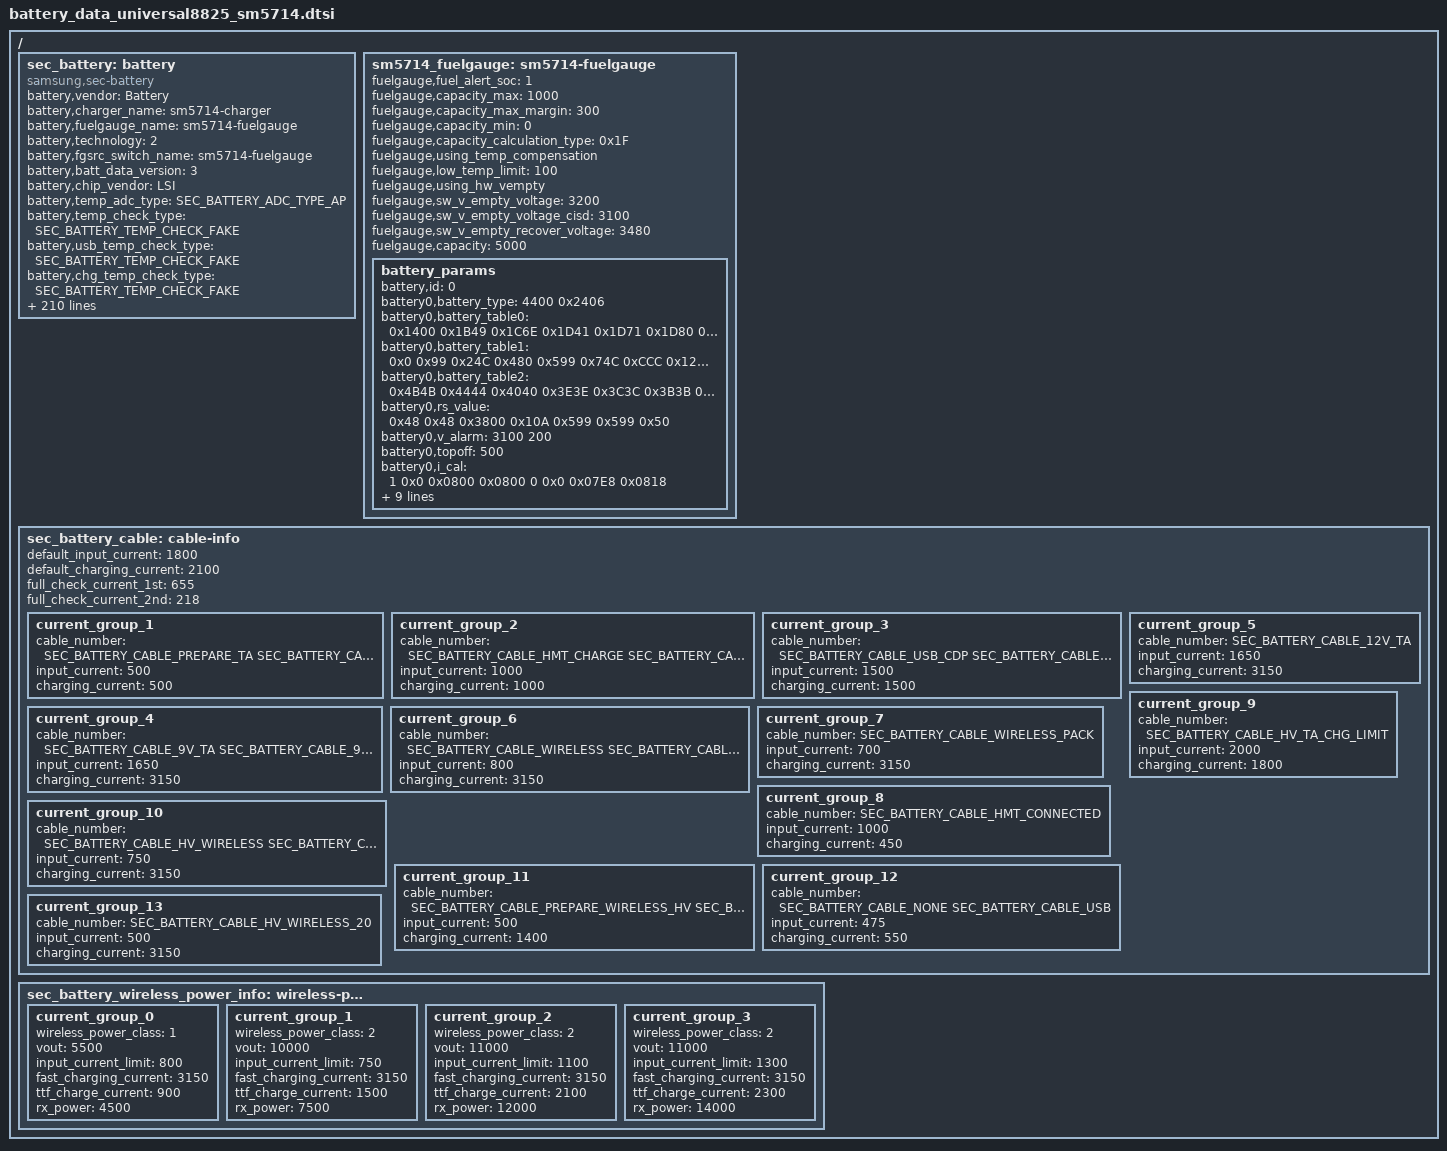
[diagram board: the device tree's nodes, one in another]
/*
 * SAMSUNG UNIVERSAL8825 board device tree source
 *
 * Copyright (c) 2020 Samsung Electronics Co., Ltd.
 *		http://www.samsung.com
 *
 * This program is free software; you can redistribute it and/or modify
 * it under the terms of the GNU General Public License version 2 as
 * published by the Free Software Foundation.
 */

#include <dt-bindings/battery/sec-battery.h>

/ {
	fragment@battery {
		target-path = "/";
		__overlay__ {
			sec_battery: battery {
				status = "okay";
				compatible = "samsung,sec-battery";

				pinctrl-names = "default";

				battery,vendor = "Battery";
				battery,charger_name = "sm5714-charger";
				battery,fuelgauge_name = "sm5714-fuelgauge";
				battery,technology = <2>; /* POWER_SUPPLY_TECHNOLOGY_LION */
				battery,fgsrc_switch_name = "sm5714-fuelgauge"; /* Fuelgauge voltage source */

				battery,batt_data_version = <3>;

				battery,chip_vendor = "LSI";
				battery,temp_adc_type = <SEC_BATTERY_ADC_TYPE_AP>;

				battery,temp_check_type = <SEC_BATTERY_TEMP_CHECK_FAKE>;
				battery,usb_temp_check_type = <SEC_BATTERY_TEMP_CHECK_FAKE>;
				battery,chg_temp_check_type = <SEC_BATTERY_TEMP_CHECK_FAKE>;
				battery,wpc_temp_check_type = <SEC_BATTERY_TEMP_CHECK_FAKE>;
				battery,dchg_temp_check_type = <SEC_BATTERY_TEMP_CHECK_FAKE>;

				battery,thermal_source = <SEC_BATTERY_THERMAL_SOURCE_ADC>;
				battery,usb_thermal_source = <SEC_BATTERY_THERMAL_SOURCE_ADC>;
				battery,chg_thermal_source = <SEC_BATTERY_THERMAL_SOURCE_ADC>;
				battery,wpc_thermal_source = <SEC_BATTERY_THERMAL_SOURCE_ADC>;
				battery,dchg_thermal_source = <SEC_BATTERY_THERMAL_SOURCE_CHG_ADC>;

				battery,polling_time = <10 30 30 30 3600>;

				battery,temp_table_adc = <311 360 416 483 562 655 763 889 1033 1162 1340 1539
					1754 1978 2219 2459 2698 2922 3123 3304 3465 3588 3679>;
				battery,temp_table_data = <900 850 800 750 700 650 600 550 500 450 400 350
					300 250 200 150 100 50 0 (-50) (-100) (-150) (-200)>;

				battery,usb_temp_table_adc = <268 326 384 453 532 624 733 859 1001 1161 1356 1558
					1774 2000 2235 2470 2692 2913 3100 3278 3431 3539 3665>;
				battery,usb_temp_table_data = <900 850 800 750 700 650 600 550 500 450 400 350
					300 250 200 150 100 50 0 (-50) (-100) (-150) (-200)>;

				battery,chg_temp_table_adc = <221 276 331 398 474 564 667 794 935 1096 1285 1489
					1711 1945 2185 2428 2665 2895 3103 3291 3446 3568 3701>;
				battery,chg_temp_table_data = <900 850 800 750 700 650 600 550 500 450 400 350
					300 250 200 150 100 50 0 (-50) (-100) (-150) (-200)>;

				battery,wpc_temp_table_adc = <311 360 416 483 562 655 763 889 1033 1162 1340 1539
					1754 1978 2219 2459 2698 2922 3123 3304 3465 3588 3679>;
				battery,wpc_temp_table_data = <900 850 800 750 700 650 600 550 500 450 400 350
					300 250 200 150 100 50 0 (-50) (-100) (-150) (-200)>;

				battery,dchg_temp_table_adc = <89148 112608 136068 164220 197064 236946 283866 337824 401166 471546 548964 640458
					736644 842214 947784 1058046 1163616 1264494 1358334 1440444 1510824 1569474 1618740>;
				battery,dchg_temp_table_data = <900 850 800 750 700 650 600 550 500 450 400 350
					300 250 200 150 100 50 0 (-50) (-100) (-150) (-200)>;

				battery,wireless_cc_cv = <85>;
				battery,wpc_cc_cv_vout = <5500>;
				battery,wpc_cv_call_vout = <5000>;
				battery,wpc_cc_call_vout = <5000>;
				battery,hv_vout_wa = <0x41>; /* WC vout 10.0V */
				battery,adc_check_count = <5>;

				battery,cable_check_type = <SEC_BATTERY_CABLE_CHECK_PSY>;
				battery,cable_source_type = <SEC_BATTERY_CABLE_SOURCE_EXTERNAL>; 
				battery,polling_type = <SEC_BATTERY_MONITOR_ALARM>;
				battery,monitor_initial_count = <0>;

				battery,battery_check_type = <0>; /* SEC_BATTERY_CHECK_NONE */
				battery,check_count = <0>;
				battery,check_adc_max = <1440>;
				battery,check_adc_min = <0>;

				battery,ovp_uvlo_check_type = <SEC_BATTERY_OVP_UVLO_CHGPOLLING>; 

				battery,temp_check_count = <1>;

				battery,overheatlimit_threshold = <700>;
				battery,overheatlimit_recovery = <680>;
				battery,wire_warm_overheat_thresh = <500>;
				battery,wire_normal_warm_thresh = <410>;
				battery,wire_cool1_normal_thresh = <180>;
				battery,wire_cool2_cool1_thresh = <150>;
				battery,wire_cool3_cool2_thresh = <50>;
				battery,wire_cold_cool3_thresh = <0>;
				battery,wireless_warm_overheat_thresh = <450>;
				battery,wireless_normal_warm_thresh = <410>;
				battery,wireless_cool1_normal_thresh = <180>;
				battery,wireless_cool2_cool1_thresh = <150>;
				battery,wireless_cool3_cool2_thresh = <50>;
				battery,wireless_cold_cool3_thresh = <0>;

				battery,wire_warm_current = <1573>;	/* 0.36C */
				battery,wire_cool1_current = <3146>;	/* 0.72C */
				battery,wire_cool2_current = <1048>;	/* 0.24C */
				battery,wire_cool3_current = <437>;	/* 0.1C */
				battery,wireless_warm_current = <1048>;		/* 0.24C */
				battery,wireless_cool1_current = <3146>;	/* 0.72C */
				battery,wireless_cool2_current = <1048>;	/* 0.24C */
				battery,wireless_cool3_current = <437>;		/* 0.1C */

				battery,tx_high_threshold = <450>;
				battery,tx_high_recovery = <400>;
				battery,tx_low_threshold = <0>;
				battery,tx_low_recovery = <50>;
				battery,full_check_type = <2>; /* SEC_BATTERY_FULLCHARGED_FUELGAUGE */
				battery,full_check_type_2nd = <2>; /* SEC_BATTERY_FULLCHARGED_FUELGAUGE */
				battery,full_check_count = <1>;
				battery,chg_gpio_full_check = <0>;
				battery,chg_polarity_full_check = <1>;

				battery,chg_high_temp = <470>;
				battery,chg_high_temp_recovery = <450>;

				battery,dchg_high_temp = <520>;
				battery,dchg_high_temp_recovery = <460>;
				battery,dchg_high_batt_temp = <400>;
				battery,dchg_high_batt_temp_recovery = <380>;

				battery,chg_input_limit_current = <1000>;
				battery,chg_charging_limit_current = <1900>;
				battery,dchg_input_limit_current = <1000>;
				battery,dchg_charging_limit_current = <2000>;

				battery,charging_limit_by_tx_check = <1>;
				battery,charging_limit_current_by_tx = <1200>;

				battery,wpc_temp_control_source = <1>; /* TEMP_CONTROL_SOURCE_BAT_THM = WPC_THM */
				battery,wpc_high_temp = <400>;
				battery,wpc_high_temp_recovery = <380>;
				battery,wpc_input_limit_current = <600>;
				battery,wpc_charging_limit_current = <1000>;
				battery,wpc_temp_lcd_on_control_source = <1>; /* TEMP_CONTROL_SOURCE_BAT_THM = WPC_THM */
				battery,wpc_lcd_on_high_temp = <400>;
				battery,wpc_lcd_on_high_temp_rec = <380>;
				battery,wpc_lcd_on_input_limit_current = <450>;

				battery,wpc_store_high_temp = <360>;
				battery,wpc_store_high_temp_recovery = <340>;
				battery,wpc_store_lcd_on_high_temp = <360>;
				battery,wpc_store_lcd_on_high_temp_rec = <300>;
				battery,wpc_store_lcd_on_charging_limit_current = <400>;

				battery,sleep_mode_limit_current = <800>;
				battery,wc_full_input_limit_current = <100>;

				battery,mix_high_temp = <420>;
				battery,mix_high_chg_temp = <500>;
				battery,mix_high_dc_temp = <580>;
				battery,mix_high_temp_recovery = <390>;

				/* SEC_BATTERY_FULL_CONDITION_NOTIMEFULL | SEC_BATTERY_FULL_CONDITION_VCELL */
				battery,full_condition_type = <9>;
				battery,full_condition_soc = <93>;
				battery,full_condition_vcell = <4330>;

				battery,recharge_check_count = <1>;
				battery,recharge_condition_type = <4>; /* SEC_BATTERY_RECHARGE_CONDITION_VCELL */
				battery,recharge_condition_soc = <98>;
				battery,recharge_condition_vcell = <4310>;

				battery,charging_total_time = <14400>;
				battery,hv_charging_total_time = <10800>;
				battery,normal_charging_total_time = <18000>;
				battery,usb_charging_total_time = <36000>;
				battery,recharging_total_time = <5400>;
				battery,charging_reset_time = <0>;

				battery,chg_float_voltage = <4380>;
				battery,chg_ocp_current = <6200>;
				battery,chg_ocp_dtc = <100>;

				battery,swelling_drop_float_voltage = <4150>;
				battery,swelling_high_rechg_voltage = <4000>;
				battery,swelling_low_rechg_voltage = <4000>;
				battery,wa_float_voltage = <4050>;

				battery,siop_event_check_type = <1>;
				battery,siop_call_cv_current = <300>;
				battery,siop_call_cc_current = <300>;

				battery,siop_input_limit_current = <1200>;
				battery,siop_charging_limit_current = <1000>;
				battery,siop_hv_input_limit_current = <700>;
				battery,siop_hv_charging_limit_current = <1000>;
				battery,siop_apdo_input_limit_current = <1200>;
				battery,siop_apdo_charging_limit_current = <2000>;

				battery,siop_wireless_input_limit_current = <600>;
				battery,siop_wireless_charging_limit_current = <850>;
				battery,siop_hv_wireless_input_limit_current = <700>;
				battery,siop_hv_wireless_charging_limit_current = <850>;
				battery,siop_store_hv_wireless_input_limit_current = <450>;
				battery,store_mode_buckoff;

				battery,ttf_hv_charge_current = <3000>;
				battery,ttf_hv_wireless_charge_current = <1500>;
				battery,ttf_wireless_charge_current = <900>;
				battery,ttf_dc25_charge_current = <4200>;
				battery,ttf_dc45_charge_current = <6000>;

				battery,rp_current_rp1 = <500>;
				battery,rp_current_rp2 = <1500>;
				battery,rp_current_rp3 = <3000>;
				battery,rp_current_rdu_rp3 = <2100>;
				battery,rp_current_abnormal_rp3 = <1800>;

				battery,pd_charging_charge_power = <15000>;
				battery,max_charging_current = <3150>;
				battery,max_charging_charge_power = <25000>; /* 25W */
				battery,battery_full_capacity = <4500>;

				/* cycle, chg_float_voltage, recharge_condition_vcell, full_condition_vcell, full_condition_soc */
				battery,age_data = <0 4380 4310 4330 93
						300 4360 4290 4310 92
						400 4340 4270 4290 91
						700 4320 4250 4270 90
						1000 4270 4200 4220 89>;

				battery,health_condition = <
					/* CYCLE ASOC */
					900 75	/* GOOD */
					1200 65 /* NORMAL */
					1500 55 /* AGED */
					>;

				/* step charging option */
				battery,step_charging_type = <0>;

				/* direct step charging option */
				battery,dc_step_chg_type = <0x6B>; /* origin(0x6B), soc option is temporary removed */
				battery,dc_step_chg_charge_power = <22000>;
				battery,dc_step_chg_step = <3>;
				battery,dc_step_chg_step_2nd = <0>;
				battery,dc_step_chg_cond_vol = <4125 4250 4380>; /*<25w 3step> STEP_CHARGING_CONDITION_VOLTAGE */ 
				battery,dc_step_chg_cond_iin = <2030 1825 0>; /* <25w 3step> STEP_CHARGING_CONDITION_INPUT_CURRENT */
				battery,dc_step_chg_val_vfloat = <4125 4250 4380>; /* <25w 3step> STEP_CHARGING_CONDITION_FLOAT_VOLTAGE */
				battery,dc_step_chg_val_iout = <5290 4090 3670>; /* <25w 3step> */
				battery,dc_step_chg_cond_soc = <20 50 100 20 50 100 20 50 100 20 50 100 20 50 100>; /* <25w 3step> STEP_CHARGING_CONDITION_SOC */

				battery,pre_afc_input_current = <500>; /* mA */
				battery,pre_afc_work_delay = <10000>;
				battery,prepare_ta_delay = <0>; /* msec */

				battery,max_input_voltage = <9000>; /* mV */
				battery,max_input_current = <3000>;  /* mA */

				battery,enable_sysovlo_irq;
				battery,enable_noise_wa;
				battery,dis_auto_shipmode_temp_ctrl;

				battery,standard_curr = <3150>;
				battery,expired_time = <10800>;
				battery,recharging_expired_time = <5400>;

				battery,cisd_max_voltage_thr = <4430>; /* battery ovp detection voltage */

				battery,cisd_alg_index = <8>;
				battery,ignore_cisd_index = <0 640>; /* Do not use BUCK_OFF, DROP_SENSOR*/
				battery,ignore_cisd_index_d = <0 80>; /* Do not use BUCK_OFF_PER_DAY, DROP_SENSOR_PER_DAY */

				battery,tx_stop_capacity = <30>;
				battery,tx_minduty_default = <20>;
				battery,tx_minduty_5V = <50>;

				battery,tx_uno_iout = <1500>;
				battery,tx_mfc_iout_gear = <1500>;
				battery,tx_mfc_iout_phone = <1100>;
				battery,tx_mfc_iout_phone_5v = <300>;
				battery,tx_mfc_iout_lcd_on = <900>;

				/* exynos_adc is not ready */
				/*io-channels = <&exynos_adc 5>, <&exynos_adc 4>, <&exynos_adc 3>, <&exynos_adc 5>, <&exynos_adc 1>;*/
				/*io-channel-names = "adc-temp", "adc-chg-temp", "adc-in-bat", "adc-wpc-temp", "adc-usb-temp";*/
				#io-channel-cells = <5>;
				/*io-channel-ranges;*/
			};

			sm5714_fuelgauge: sm5714-fuelgauge {
				status = "okay";
				fuelgauge,fuel_alert_soc = <1>;
				fuelgauge,capacity_max = <1000>;
				fuelgauge,capacity_max_margin = <300>;
				fuelgauge,capacity_min = <0>;
				fuelgauge,capacity_calculation_type = <0x1F>;
				fuelgauge,using_temp_compensation;
				fuelgauge,low_temp_limit = <100>;
				fuelgauge,using_hw_vempty;
				fuelgauge,sw_v_empty_voltage = <3200>;
				fuelgauge,sw_v_empty_voltage_cisd = <3100>;
				fuelgauge,sw_v_empty_recover_voltage = <3480>;
				fuelgauge,capacity = <5000>;
				battery_params {
					battery,id = <0>;
					battery0,battery_type = <4400 0x2406>; /* V_max cap*/
					battery0,battery_table0 = <
						0x1400 0x1B49 0x1C6E 0x1D41 0x1D71 0x1D80 0x1D94 0x1DDA
						0x1E17 0x1E3B 0x1E53 0x1E71 0x1E97 0x1EE7 0x1F14 0x1F58
						0x1FB5 0x1FEC 0x2025 0x2095 0x20E3 0x2122 0x2226 0x2400
						>;
					battery0,battery_table1 = <
						0x0 0x99 0x24C 0x480 0x599 0x74C 0xCCC 0x1266
						0x1AB3 0x204C 0x25CC 0x2B66 0x30E6 0x3933 0x3C00 0x3ECC
						0x4466 0x49E6 0x4CB3 0x4F80 0x5500 0x57CC 0x6400 0x6419
						>;
					battery0,battery_table2 = <
						0x4B4B 0x4444 0x4040 0x3E3E 0x3C3C 0x3B3B 0x3838 0x3737
						0x3535 0x3434 0x3434 0x3333 0x3333 0x3333 0x3333 0x3232
						>;
					/*spare min max factor chg_factor dischg_factor manvalue*/
					battery0,rs_value = <0x48 0x48 0x3800 0x10A 0x599 0x599 0x50>;
					battery0,v_alarm = <3100 200>;
					battery0,topoff = <500>;
					battery0,i_cal = <1 0x0 0x0800 0x0800 0 0x0 0x07E8 0x0818>;
					battery0,v_cal = <1 0 0 1 0 0 0>;
					battery0,temp_std = <25>;
					battery0,tem_poff = <3400 50 3250 50>;
					battery0,aux_ctrl = <0x322 0x5800>;
					battery0,data_ver = <3>;
					battery0,v_max_table = <0x2226 0x2203 0x21E0 0x21BC 0x2165>;
					battery0,q_max_table = <0x2406 0x235F 0x22B9 0x2212 0x2071>;
				};
			};

			/* sec_battery_cable
			 *   0	UNKNOWN,
			 *   1	NONE,
			 *   2	PREPARE_TA,
			 *   3	TA,
			 *   4	USB,
			 *   5	USB_CDP,
			 *   6	9V_TA,
			 *   7	9V_ERR,
			 *   8	9V_UNKNOWN,
			 *   9	12V_TA,
			 *  10	WIRELESS,
			 *  11	HV_WIRELESS,
			 *  12	PMA_WIRELESS,
			 *  13	WIRELESS_PACK,
			 *  14	WIRELESS_HV_PACK,
			 *  15	WIRELESS_STAND,
			 *  16	WIRELESS_HV_STAND,
			 *  17	QC20,
			 *  18	QC30,
			 *  19	PDIC,
			 *  20	UARTOFF,
			 *  21	OTG,
			 *  22	LAN_HUB,
			 *  23	POWER_SHARING,
			 *  24	HMT_CONNECTED,
			 *  25	HMT_CHARGE,
			 *  26	HV_TA_CHG_LIMIT,
			 *  27	WIRELESS_VEHICLE,
			 *  28	WIRELESS_HV_VEHICLE,
			 *  29	PREPARE_WIRELESS_HV,
			 *  30	TIMEOUT,
			 *  31	SMART_OTG,
			 *  32	SMART_NOTG,
			 *  33	WIRELESS_TX,
			 *  34	HV_WIRELESS_20,
			 *  35	HV_WIRELESS_20_LIMIT,
			 *  36	WIRELESS_FAKE,
			 *  37  PREPARE_WIRELESS_20,
			 *  38	CABLE_PDIC_APDO,
			 *  39	CABLE_MAX,
			 */

			sec_battery_cable: cable-info {
				default_input_current = <1800>;
				default_charging_current = <2100>;
				full_check_current_1st = <655>;
				full_check_current_2nd = <218>;

				current_group_1 {
					cable_number = <
						SEC_BATTERY_CABLE_PREPARE_TA
						SEC_BATTERY_CABLE_PDIC
						SEC_BATTERY_CABLE_OTG
						SEC_BATTERY_CABLE_LAN_HUB
						SEC_BATTERY_CABLE_POWER_SHARING
						SEC_BATTERY_CABLE_TIMEOUT>;
					input_current = <500>;
					charging_current = <500>;
				};
				current_group_2 {
					cable_number = <
						SEC_BATTERY_CABLE_HMT_CHARGE
						SEC_BATTERY_CABLE_SMART_OTG>;
					input_current = <1000>;
					charging_current = <1000>;
				};
				current_group_3 {
					cable_number = <
						SEC_BATTERY_CABLE_USB_CDP
						SEC_BATTERY_CABLE_SMART_NOTG>;
					input_current = <1500>;
					charging_current = <1500>;
				};
				current_group_4 {
					cable_number = <
						SEC_BATTERY_CABLE_9V_TA
						SEC_BATTERY_CABLE_9V_ERR
						SEC_BATTERY_CABLE_9V_UNKNOWN>;
					input_current = <1650>;
					charging_current = <3150>;
				};
				current_group_5 {
					cable_number = <SEC_BATTERY_CABLE_12V_TA>;
					input_current = <1650>;
					charging_current = <3150>;
				};
				current_group_6 {
					cable_number = <
						SEC_BATTERY_CABLE_WIRELESS
						SEC_BATTERY_CABLE_PMA_WIRELESS
						SEC_BATTERY_CABLE_WIRELESS_STAND
						SEC_BATTERY_CABLE_WIRELESS_VEHICLE
						SEC_BATTERY_CABLE_WIRELESS_TX
						SEC_BATTERY_CABLE_HV_WIRELESS_20_LIMIT>;
					input_current = <800>;
					charging_current = <3150>;
				};
				current_group_7 {
					cable_number = <SEC_BATTERY_CABLE_WIRELESS_PACK>;
					input_current = <700>;
					charging_current = <3150>;
				};
				current_group_8 {
					cable_number = <SEC_BATTERY_CABLE_HMT_CONNECTED>;
					input_current = <1000>;
					charging_current = <450>;
				};
				current_group_9 {
					cable_number = <SEC_BATTERY_CABLE_HV_TA_CHG_LIMIT>;
					input_current = <2000>;
					charging_current = <1800>;
				};
				current_group_10 {
					cable_number = <
						SEC_BATTERY_CABLE_HV_WIRELESS
						SEC_BATTERY_CABLE_WIRELESS_HV_PACK
						SEC_BATTERY_CABLE_WIRELESS_HV_STAND
						SEC_BATTERY_CABLE_WIRELESS_HV_VEHICLE>;
					input_current = <750>;
					charging_current = <3150>;
				};
				current_group_11 {
					cable_number = <
						SEC_BATTERY_CABLE_PREPARE_WIRELESS_HV
						SEC_BATTERY_CABLE_WIRELESS_FAKE
						SEC_BATTERY_CABLE_PREPARE_WIRELESS_20>;
					input_current = <500>;
					charging_current = <1400>;
				};
				current_group_12 {
					cable_number = <
						SEC_BATTERY_CABLE_NONE
						SEC_BATTERY_CABLE_USB>;
					input_current = <475>;
					charging_current = <550>;
				};
				current_group_13 {
					cable_number = <SEC_BATTERY_CABLE_HV_WIRELESS_20>;
					input_current = <500>;
					charging_current = <3150>;
				};
			};
			sec_battery_wireless_power_info: wireless-power-info {
				current_group_0 {
					wireless_power_class = <1>;
					vout = <5500>;
					input_current_limit = <800>;
					fast_charging_current = <3150>;
					ttf_charge_current = <900>;
					rx_power = <4500>;
				};
				current_group_1 {
					wireless_power_class = <2>;
					vout = <10000>;
					input_current_limit = <750>;
					fast_charging_current = <3150>;
					ttf_charge_current = <1500>;
					rx_power = <7500>;
				};
				current_group_2 {
					wireless_power_class = <2>;
					vout = <11000>;
					input_current_limit = <1100>;
					fast_charging_current = <3150>;
					ttf_charge_current = <2100>;
					rx_power = <12000>;
				};
				current_group_3 {
					wireless_power_class = <2>;
					vout = <11000>;
					input_current_limit = <1300>;
					fast_charging_current = <3150>;
					ttf_charge_current = <2300>;
					rx_power = <14000>;
				};
			};
		}; /* end of __overlay__ */
	}; /* end of fragment */
};
